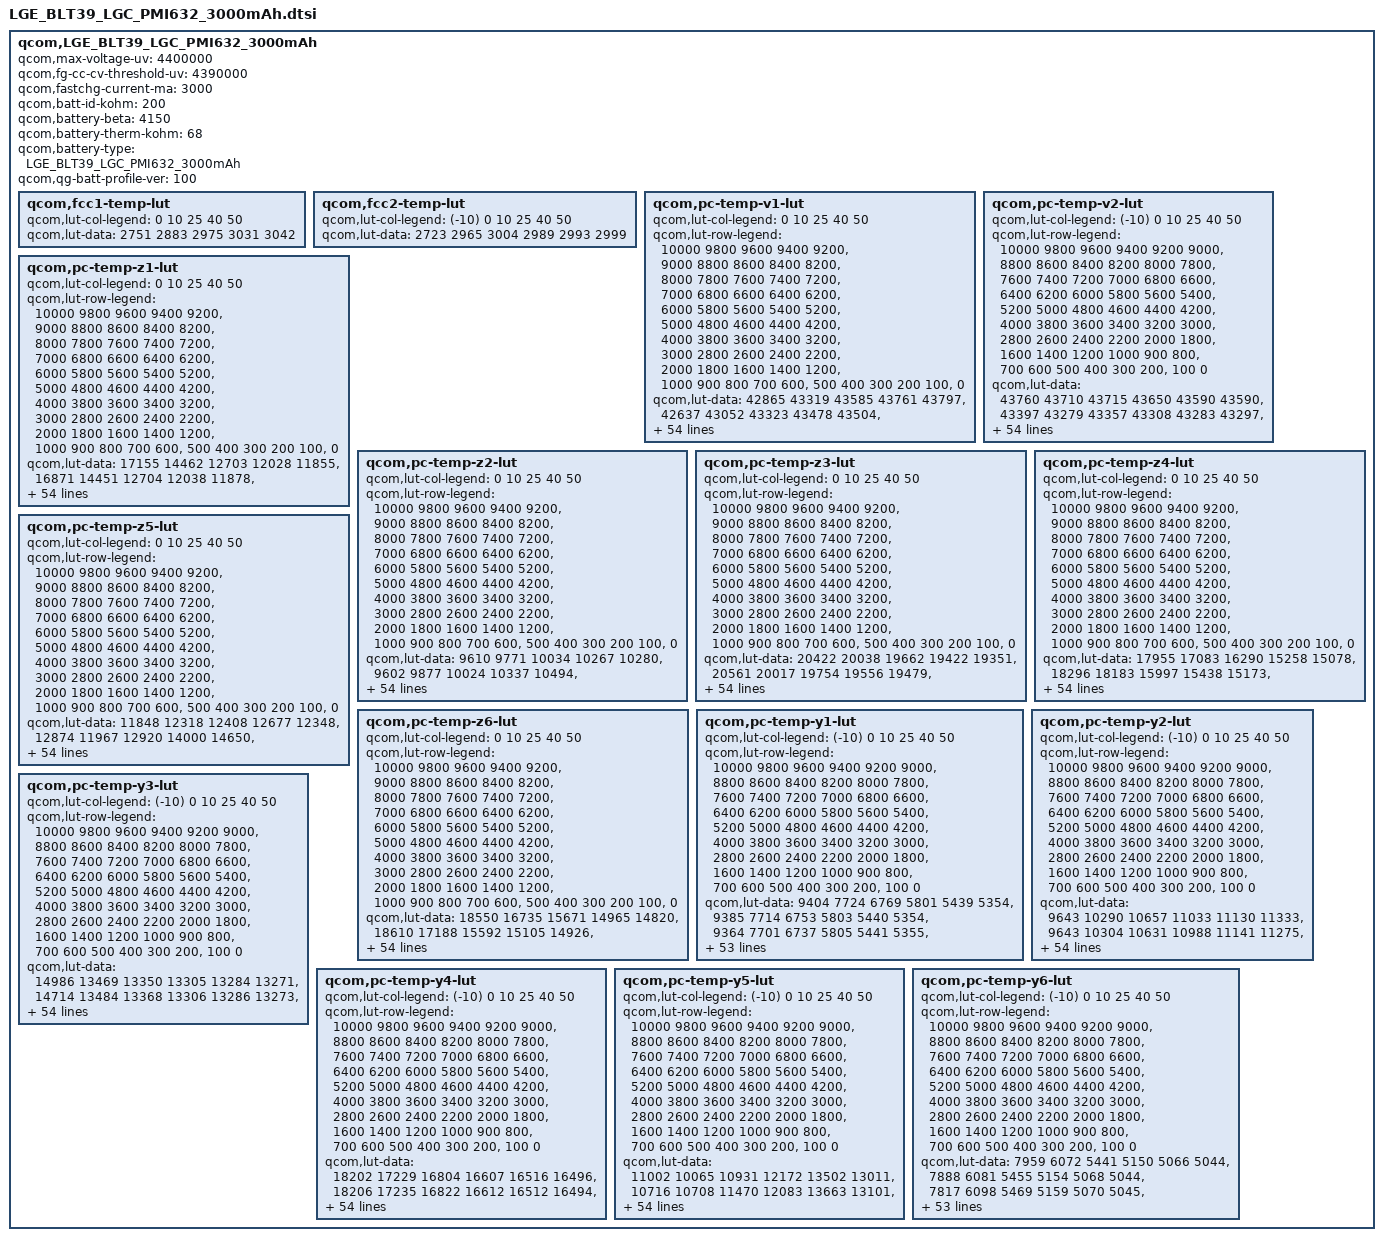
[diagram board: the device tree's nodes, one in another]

qcom,LGE_BLT39_LGC_PMI632_3000mAh {
    /* 3869837_LGE_BLT39lgc_3000mAh_averaged_MasterSlave_Feb22nd2019 */
    qcom,max-voltage-uv = <4400000>;
    qcom,fg-cc-cv-threshold-uv = <4390000>;
    qcom,fastchg-current-ma = <3000>;
    qcom,batt-id-kohm = <200>;
    qcom,battery-beta = <4150>;
    qcom,battery-therm-kohm = <68>;
    qcom,battery-type = "LGE_BLT39_LGC_PMI632_3000mAh";
    qcom,qg-batt-profile-ver = <100>;

	qcom,fcc1-temp-lut {
		qcom,lut-col-legend = <0 10 25 40 50>;
		qcom,lut-data = <2751 2883 2975 3031 3042>;
	};

	qcom,fcc2-temp-lut {
		qcom,lut-col-legend = <(-10) 0 10 25 40 50>;
		qcom,lut-data = <2723 2965 3004 2989 2993 2999>;
	};

	qcom,pc-temp-v1-lut {
		qcom,lut-col-legend = <0 10 25 40 50>;
		qcom,lut-row-legend = <10000 9800 9600 9400 9200>,
			<9000 8800 8600 8400 8200>,
			<8000 7800 7600 7400 7200>,
			<7000 6800 6600 6400 6200>,
			<6000 5800 5600 5400 5200>,
			<5000 4800 4600 4400 4200>,
			<4000 3800 3600 3400 3200>,
			<3000 2800 2600 2400 2200>,
			<2000 1800 1600 1400 1200>,
			<1000 900 800 700 600>,
			<500 400 300 200 100>,
			<0>;
		qcom,lut-data = <42865 43319 43585 43761 43797>,
			<42637 43052 43323 43478 43504>,
			<42409 42795 43070 43224 43248>,
			<42184 42546 42827 42980 43007>,
			<41964 42299 42591 42741 42770>,
			<41745 42058 42358 42508 42540>,
			<41533 41829 42128 42276 42310>,
			<41338 41609 41903 42045 42080>,
			<41159 41401 41681 41819 41853>,
			<40968 41215 41464 41595 41629>,
			<40730 41054 41261 41374 41408>,
			<40460 40877 41081 41160 41192>,
			<40206 40649 40895 40950 40978>,
			<39959 40399 40665 40746 40771>,
			<39736 40188 40408 40540 40571>,
			<39584 40002 40200 40340 40378>,
			<39483 39843 40043 40158 40192>,
			<39391 39722 39902 39990 40015>,
			<39274 39622 39755 39828 39845>,
			<39141 39514 39610 39673 39686>,
			<39011 39390 39464 39519 39530>,
			<38891 39264 39318 39362 39367>,
			<38775 39146 39172 39205 39198>,
			<38669 39034 39022 39027 39021>,
			<38570 38925 38870 38792 38814>,
			<38481 38815 38716 38580 38621>,
			<38406 38708 38545 38473 38504>,
			<38341 38610 38394 38402 38423>,
			<38285 38519 38299 38335 38344>,
			<38236 38438 38230 38266 38257>,
			<38193 38374 38180 38201 38176>,
			<38151 38318 38147 38139 38106>,
			<38109 38268 38119 38081 38045>,
			<38068 38223 38091 38029 37989>,
			<38033 38180 38066 37986 37941>,
			<38001 38139 38035 37944 37893>,
			<37975 38099 37998 37898 37833>,
			<37960 38053 37952 37851 37765>,
			<37952 37993 37885 37787 37690>,
			<37940 37920 37783 37696 37611>,
			<37888 37826 37673 37590 37521>,
			<37789 37696 37565 37475 37411>,
			<37674 37555 37443 37345 37281>,
			<37531 37405 37284 37185 37121>,
			<37372 37279 37151 37049 36985>,
			<37265 37186 37073 36975 36911>,
			<37225 37151 37048 36955 36893>,
			<37187 37123 37035 36945 36881>,
			<37144 37092 37012 36924 36861>,
			<37061 37030 36954 36861 36798>,
			<36839 36808 36695 36591 36524>,
			<36407 36358 36265 36157 36093>,
			<35831 35788 35696 35582 35527>,
			<35061 35014 34918 34798 34755>,
			<33812 33791 33706 33579 33568>,
			<30000 30000 30000 30000 30000>;
	};

	qcom,pc-temp-v2-lut {
		qcom,lut-col-legend = <(-10) 0 10 25 40 50>;
		qcom,lut-row-legend = <10000 9800 9600 9400 9200 9000>,
			<8800 8600 8400 8200 8000 7800>,
			<7600 7400 7200 7000 6800 6600>,
			<6400 6200 6000 5800 5600 5400>,
			<5200 5000 4800 4600 4400 4200>,
			<4000 3800 3600 3400 3200 3000>,
			<2800 2600 2400 2200 2000 1800>,
			<1600 1400 1200 1000 900 800>,
			<700 600 500 400 300 200>,
			<100 0>;
		qcom,lut-data = <43760 43710 43715 43650 43590 43590>,
			<43397 43279 43357 43308 43283 43297>,
			<43057 42900 43035 43000 43000 43025>,
			<42741 42583 42755 42732 42743 42772>,
			<42439 42318 42511 42498 42511 42541>,
			<42165 42072 42279 42274 42287 42315>,
			<41941 41827 42048 42046 42059 42087>,
			<41757 41593 41825 41823 41835 41863>,
			<41579 41370 41604 41603 41614 41641>,
			<41369 41155 41384 41385 41395 41423>,
			<41139 40954 41179 41175 41180 41209>,
			<40930 40788 41007 40984 40972 40998>,
			<40775 40634 40839 40797 40768 40791>,
			<40632 40405 40614 40583 40566 40591>,
			<40428 39998 40313 40328 40362 40394>,
			<40035 39638 40033 40101 40169 40206>,
			<39612 39482 39811 39943 39997 40028>,
			<39370 39378 39616 39807 39833 39857>,
			<39224 39252 39441 39649 39672 39692>,
			<39093 39086 39287 39467 39519 39537>,
			<38936 38916 39135 39278 39352 39370>,
			<38770 38761 38977 39079 39141 39165>,
			<38613 38614 38822 38880 38917 38949>,
			<38465 38469 38679 38717 38741 38773>,
			<38327 38319 38545 38580 38599 38623>,
			<38215 38182 38423 38461 38477 38494>,
			<38125 38074 38312 38356 38372 38386>,
			<38050 37981 38209 38263 38278 38291>,
			<37988 37912 38114 38176 38192 38202>,
			<37938 37864 38024 38095 38114 38121>,
			<37893 37824 37943 38021 38041 38047>,
			<37848 37786 37867 37954 37973 37979>,
			<37804 37751 37800 37892 37909 37915>,
			<37759 37714 37751 37828 37843 37850>,
			<37713 37674 37716 37762 37779 37786>,
			<37665 37630 37678 37698 37709 37711>,
			<37613 37583 37634 37640 37622 37606>,
			<37557 37530 37585 37586 37526 37486>,
			<37495 37473 37528 37522 37441 37392>,
			<37429 37412 37464 37451 37370 37318>,
			<37358 37345 37388 37369 37293 37239>,
			<37277 37271 37285 37262 37188 37135>,
			<37185 37188 37174 37136 37065 37014>,
			<37081 37099 37074 36992 36911 36854>,
			<36955 37000 36987 36901 36831 36778>,
			<36800 36886 36905 36868 36806 36755>,
			<36703 36819 36875 36852 36793 36741>,
			<36584 36749 36839 36826 36770 36719>,
			<36431 36659 36779 36752 36711 36666>,
			<36216 36517 36631 36512 36494 36487>,
			<35919 36246 36265 36088 36097 36104>,
			<35520 35813 35767 35542 35570 35603>,
			<34899 35178 35116 34840 34940 35001>,
			<33975 34261 34265 34070 34217 34311>,
			<32665 33075 33135 33055 33051 33209>,
			<28045 27812 27718 27711 27670 29741>;
	};

	qcom,pc-temp-z1-lut {
		qcom,lut-col-legend = <0 10 25 40 50>;
		qcom,lut-row-legend = <10000 9800 9600 9400 9200>,
			<9000 8800 8600 8400 8200>,
			<8000 7800 7600 7400 7200>,
			<7000 6800 6600 6400 6200>,
			<6000 5800 5600 5400 5200>,
			<5000 4800 4600 4400 4200>,
			<4000 3800 3600 3400 3200>,
			<3000 2800 2600 2400 2200>,
			<2000 1800 1600 1400 1200>,
			<1000 900 800 700 600>,
			<500 400 300 200 100>,
			<0>;
		qcom,lut-data = <17155 14462 12703 12028 11855>,
			<16871 14451 12704 12038 11878>,
			<16754 14448 12702 12041 11885>,
			<16665 14443 12698 12042 11890>,
			<16593 14433 12695 12043 11896>,
			<16520 14414 12692 12044 11901>,
			<16455 14392 12689 12045 11904>,
			<16411 14363 12688 12047 11905>,
			<16373 14335 12690 12048 11906>,
			<16324 14317 12696 12049 11907>,
			<16217 14304 12704 12050 11908>,
			<16056 14294 12717 12052 11909>,
			<15943 14274 12727 12057 11911>,
			<15886 14248 12715 12060 11913>,
			<15840 14237 12684 12058 11914>,
			<15784 14227 12673 12054 11916>,
			<15706 14221 12681 12055 11917>,
			<15632 14232 12693 12060 11919>,
			<15579 14261 12706 12064 11920>,
			<15534 14295 12721 12066 11923>,
			<15507 14347 12730 12067 11925>,
			<15506 14397 12734 12069 11926>,
			<15517 14414 12738 12072 11927>,
			<15521 14424 12745 12075 11928>,
			<15499 14432 12757 12079 11930>,
			<15475 14450 12765 12083 11934>,
			<15479 14476 12769 12086 11937>,
			<15513 14493 12773 12089 11942>,
			<15541 14504 12779 12093 11946>,
			<15538 14515 12786 12099 11950>,
			<15524 14531 12793 12105 11954>,
			<15520 14551 12800 12110 11958>,
			<15542 14570 12807 12116 11962>,
			<15573 14592 12814 12120 11964>,
			<15590 14609 12820 12124 11965>,
			<15598 14611 12828 12127 11966>,
			<15609 14610 12839 12131 11968>,
			<15654 14609 12853 12135 11970>,
			<15784 14621 12866 12138 11972>,
			<15887 14641 12880 12140 11974>,
			<15918 14647 12892 12143 11976>,
			<15936 14629 12901 12147 11979>,
			<15955 14625 12907 12151 11982>,
			<15976 14646 12910 12154 11984>,
			<15961 14622 12917 12158 11987>,
			<16020 14631 12924 12163 11989>,
			<16030 14628 12930 12163 11990>,
			<15969 14630 12930 12165 11992>,
			<16001 14600 12937 12167 11993>,
			<16021 14604 12948 12170 11995>,
			<16021 14667 12958 12178 12000>,
			<16056 14653 12985 12190 12011>,
			<16043 14677 13007 12209 12026>,
			<16038 14711 13065 12239 12049>,
			<16038 14711 13065 12239 12049>,
			<16038 14711 13065 12239 12049>;
	};

	qcom,pc-temp-z2-lut {
		qcom,lut-col-legend = <0 10 25 40 50>;
		qcom,lut-row-legend = <10000 9800 9600 9400 9200>,
			<9000 8800 8600 8400 8200>,
			<8000 7800 7600 7400 7200>,
			<7000 6800 6600 6400 6200>,
			<6000 5800 5600 5400 5200>,
			<5000 4800 4600 4400 4200>,
			<4000 3800 3600 3400 3200>,
			<3000 2800 2600 2400 2200>,
			<2000 1800 1600 1400 1200>,
			<1000 900 800 700 600>,
			<500 400 300 200 100>,
			<0>;
		qcom,lut-data = <9610 9771 10034 10267 10280>,
			<9602 9877 10024 10337 10494>,
			<9618 9837 10022 10291 10453>,
			<9649 9800 10030 10242 10408>,
			<9669 9794 10054 10204 10393>,
			<9682 9792 10085 10172 10384>,
			<9692 9791 10139 10172 10383>,
			<9699 9789 10179 10201 10403>,
			<9705 9789 10161 10233 10427>,
			<9709 9787 10111 10259 10442>,
			<9704 9785 10066 10283 10455>,
			<9690 9785 10026 10303 10463>,
			<9684 9795 9997 10322 10448>,
			<9696 9813 9984 10332 10431>,
			<9712 9814 9976 10298 10409>,
			<9718 9788 9974 10256 10378>,
			<9720 9765 9980 10264 10382>,
			<9722 9767 9992 10291 10406>,
			<9726 9773 10018 10315 10422>,
			<9732 9778 10063 10329 10431>,
			<9738 9787 10081 10344 10447>,
			<9741 9799 10082 10391 10518>,
			<9744 9809 10082 10481 10735>,
			<9744 9821 10097 10515 10845>,
			<9741 9830 10139 10494 10711>,
			<9735 9839 10160 10456 10544>,
			<9729 9847 10151 10388 10531>,
			<9721 9849 10139 10274 10559>,
			<9712 9847 10147 10247 10588>,
			<9704 9844 10170 10492 10646>,
			<9695 9838 10184 10733 10699>,
			<9686 9827 10186 10670 10676>,
			<9677 9819 10186 10485 10596>,
			<9667 9814 10194 10424 10569>,
			<9655 9811 10213 10440 10641>,
			<9642 9811 10221 10467 10755>,
			<9622 9815 10213 10516 10898>,
			<9564 9822 10202 10594 11067>,
			<9416 9844 10205 10650 11115>,
			<9287 9877 10226 10695 11102>,
			<9233 9900 10242 10719 11084>,
			<9197 9914 10247 10705 11066>,
			<9171 9933 10253 10685 11046>,
			<9159 9967 10266 10724 11033>,
			<9169 9804 10331 10773 10955>,
			<9170 9735 10356 10746 10801>,
			<9171 9730 10356 10737 10786>,
			<9170 9715 10272 10601 10803>,
			<9159 9703 10318 10603 10842>,
			<9153 9705 10333 10672 11027>,
			<9169 9696 10449 10825 10842>,
			<9192 9631 10294 10752 10630>,
			<9182 9530 10248 10617 10523>,
			<9153 9433 10123 10440 10370>,
			<9153 9433 10123 10440 10370>,
			<9153 9433 10123 10440 10370>;
	};

	qcom,pc-temp-z3-lut {
		qcom,lut-col-legend = <0 10 25 40 50>;
		qcom,lut-row-legend = <10000 9800 9600 9400 9200>,
			<9000 8800 8600 8400 8200>,
			<8000 7800 7600 7400 7200>,
			<7000 6800 6600 6400 6200>,
			<6000 5800 5600 5400 5200>,
			<5000 4800 4600 4400 4200>,
			<4000 3800 3600 3400 3200>,
			<3000 2800 2600 2400 2200>,
			<2000 1800 1600 1400 1200>,
			<1000 900 800 700 600>,
			<500 400 300 200 100>,
			<0>;
		qcom,lut-data = <20422 20038 19662 19422 19351>,
			<20561 20017 19754 19556 19479>,
			<20605 19975 19810 19594 19515>,
			<20632 19944 19825 19609 19529>,
			<20637 19952 19834 19612 19528>,
			<20630 19977 19834 19614 19521>,
			<20617 19988 19817 19609 19512>,
			<20599 19984 19794 19582 19499>,
			<20568 19977 19774 19553 19484>,
			<20541 19966 19754 19533 19467>,
			<20531 19949 19735 19514 19448>,
			<20525 19931 19716 19498 19433>,
			<20516 19914 19697 19484 19417>,
			<20496 19899 19673 19469 19403>,
			<20466 19887 19647 19451 19383>,
			<20427 19879 19627 19434 19363>,
			<20363 19870 19612 19424 19355>,
			<20300 19849 19600 19415 19352>,
			<20261 19815 19585 19408 19350>,
			<20233 19786 19571 19401 19349>,
			<20210 19760 19567 19396 19348>,
			<20190 19742 19573 19403 19355>,
			<20173 19741 19583 19427 19385>,
			<20161 19752 19595 19445 19400>,
			<20153 19770 19615 19457 19394>,
			<20145 19829 19629 19465 19380>,
			<20135 19919 19639 19452 19361>,
			<20120 19966 19645 19413 19331>,
			<20104 19996 19643 19394 19321>,
			<20086 20012 19635 19392 19372>,
			<20066 20008 19625 19396 19428>,
			<20047 19992 19612 19418 19429>,
			<20028 19975 19598 19462 19416>,
			<20008 19957 19587 19475 19403>,
			<19985 19937 19578 19461 19388>,
			<19961 19913 19574 19446 19377>,
			<19928 19886 19578 19438 19381>,
			<19874 19858 19584 19432 19391>,
			<19780 19822 19584 19431 19394>,
			<19690 19787 19581 19431 19389>,
			<19620 19780 19577 19432 19382>,
			<19568 19787 19566 19425 19370>,
			<19563 19785 19552 19416 19359>,
			<19566 19731 19536 19418 19364>,
			<19558 19493 19505 19410 19360>,
			<19552 19412 19475 19388 19345>,
			<19538 19396 19467 19384 19345>,
			<19527 19374 19376 19352 19332>,
			<19516 19366 19354 19353 19327>,
			<19503 19364 19368 19346 19318>,
			<19526 19372 19386 19328 19327>,
			<19582 19402 19360 19329 19336>,
			<19600 19421 19354 19342 19340>,
			<19669 19428 19353 19349 19354>,
			<19669 19428 19353 19349 19354>,
			<19669 19428 19353 19349 19354>;
	};

	qcom,pc-temp-z4-lut {
		qcom,lut-col-legend = <0 10 25 40 50>;
		qcom,lut-row-legend = <10000 9800 9600 9400 9200>,
			<9000 8800 8600 8400 8200>,
			<8000 7800 7600 7400 7200>,
			<7000 6800 6600 6400 6200>,
			<6000 5800 5600 5400 5200>,
			<5000 4800 4600 4400 4200>,
			<4000 3800 3600 3400 3200>,
			<3000 2800 2600 2400 2200>,
			<2000 1800 1600 1400 1200>,
			<1000 900 800 700 600>,
			<500 400 300 200 100>,
			<0>;
		qcom,lut-data = <17955 17083 16290 15258 15078>,
			<18296 18183 15997 15438 15173>,
			<18021 17780 15759 15304 15108>,
			<17509 17277 15581 15165 15023>,
			<17158 16923 15436 15084 14962>,
			<16942 16604 15323 15021 14907>,
			<16766 16358 15229 14978 14881>,
			<16606 16179 15156 14946 14869>,
			<16456 16031 15102 14925 14861>,
			<16348 15888 15059 14912 14855>,
			<16293 15751 15029 14904 14849>,
			<16256 15648 15005 14897 14844>,
			<16209 15581 14991 14890 14836>,
			<16131 15531 14995 14883 14831>,
			<16039 15492 15005 14877 14832>,
			<15953 15461 15006 14872 14830>,
			<15857 15435 14965 14863 14822>,
			<15791 15406 14920 14844 14805>,
			<15785 15377 14911 14829 14787>,
			<15786 15368 14907 14818 14772>,
			<15788 15377 14901 14809 14760>,
			<15791 15387 14882 14800 14757>,
			<15799 15383 14865 14788 14756>,
			<15809 15357 14865 14788 14757>,
			<15831 15321 14868 14890 14849>,
			<15856 15246 14875 15002 14964>,
			<15868 15146 14938 15011 14979>,
			<15877 15092 15007 15010 14981>,
			<15882 15060 15014 15008 14979>,
			<15883 15039 15011 14985 14901>,
			<15882 15032 15005 14950 14806>,
			<15882 15028 14988 14899 14778>,
			<15881 15024 14961 14827 14764>,
			<15880 15017 14937 14797 14759>,
			<15878 15011 14913 14789 14757>,
			<15872 15005 14888 14785 14757>,
			<15866 15000 14855 14786 14765>,
			<15869 14995 14828 14790 14786>,
			<15877 14986 14829 14796 14798>,
			<15883 14975 14846 14814 14804>,
			<15877 14957 14855 14828 14807>,
			<15856 14920 14844 14824 14804>,
			<15788 14907 14834 14815 14799>,
			<15615 14913 14835 14809 14797>,
			<15312 15019 14805 14788 14784>,
			<15312 15069 14774 14755 14753>,
			<15318 15077 14764 14735 14728>,
			<15316 15084 14842 14732 14705>,
			<15311 15078 14847 14705 14681>,
			<15300 15065 14824 14721 14703>,
			<15270 15061 14854 14794 14735>,
			<15270 15095 14911 14797 14728>,
			<15344 15113 14928 14786 14723>,
			<15363 15148 14945 14781 14711>,
			<15363 15148 14945 14781 14711>,
			<15363 15148 14945 14781 14711>;
	};

	qcom,pc-temp-z5-lut {
		qcom,lut-col-legend = <0 10 25 40 50>;
		qcom,lut-row-legend = <10000 9800 9600 9400 9200>,
			<9000 8800 8600 8400 8200>,
			<8000 7800 7600 7400 7200>,
			<7000 6800 6600 6400 6200>,
			<6000 5800 5600 5400 5200>,
			<5000 4800 4600 4400 4200>,
			<4000 3800 3600 3400 3200>,
			<3000 2800 2600 2400 2200>,
			<2000 1800 1600 1400 1200>,
			<1000 900 800 700 600>,
			<500 400 300 200 100>,
			<0>;
		qcom,lut-data = <11848 12318 12408 12677 12348>,
			<12874 11967 12920 14000 14650>,
			<13759 12415 13342 14584 15471>,
			<14576 13065 13654 14976 15951>,
			<15369 13767 13914 15335 16423>,
			<16141 14611 14187 15595 16809>,
			<16888 15305 14497 15644 16885>,
			<17640 15835 14767 15640 16695>,
			<18427 16275 14965 15620 16410>,
			<19030 16647 15126 15439 16009>,
			<19329 16995 15204 15143 15516>,
			<19529 17156 15193 14964 15225>,
			<19823 16879 15103 14823 14977>,
			<20489 16321 14771 14660 14786>,
			<21286 15889 14195 14393 14329>,
			<21799 15545 14023 14173 13710>,
			<22199 15219 14507 14220 13633>,
			<22441 14901 15091 14455 13859>,
			<22434 14589 15316 14593 14163>,
			<22335 14260 15448 14725 14463>,
			<22209 13843 15691 14990 14915>,
			<22033 13487 16535 16068 16681>,
			<21770 13372 17923 18971 21708>,
			<21478 13392 20219 21754 24279>,
			<21136 13538 23981 24677 22925>,
			<20757 14694 27051 26770 20504>,
			<20378 16821 29578 24968 17907>,
			<19965 18686 31264 19327 14710>,
			<19545 20868 30863 16261 13502>,
			<19132 22307 28777 15182 15080>,
			<18708 22276 26616 14619 17302>,
			<18306 21996 24486 15869 18558>,
			<17958 21696 22536 19253 19505>,
			<17611 21238 21323 21182 20313>,
			<17185 20624 20381 21969 20928>,
			<16670 19932 20053 22535 21611>,
			<16023 19072 21072 23097 23119>,
			<15045 18375 22829 23591 25238>,
			<13529 17762 24425 23579 25643>,
			<12264 17189 26195 22268 22757>,
			<11570 17361 26963 20765 19532>,
			<11121 19465 24480 19834 17975>,
			<11022 20141 21623 19201 17032>,
			<11003 18176 20394 18977 16778>,
			<11596 13355 20310 19008 16682>,
			<11536 11950 18854 18622 16699>,
			<11418 11738 18237 18682 17571>,
			<11346 11503 13098 16016 17453>,
			<11269 11449 12551 17364 19213>,
			<11216 11461 13088 16280 16512>,
			<11437 11631 13640 13120 14102>,
			<11768 11794 12270 12794 14290>,
			<11517 11682 11982 12995 14363>,
			<11474 11502 11753 13092 15302>,
			<11474 11502 11753 13092 15302>,
			<11474 11502 11753 13092 15302>;
	};

	qcom,pc-temp-z6-lut {
		qcom,lut-col-legend = <0 10 25 40 50>;
		qcom,lut-row-legend = <10000 9800 9600 9400 9200>,
			<9000 8800 8600 8400 8200>,
			<8000 7800 7600 7400 7200>,
			<7000 6800 6600 6400 6200>,
			<6000 5800 5600 5400 5200>,
			<5000 4800 4600 4400 4200>,
			<4000 3800 3600 3400 3200>,
			<3000 2800 2600 2400 2200>,
			<2000 1800 1600 1400 1200>,
			<1000 900 800 700 600>,
			<500 400 300 200 100>,
			<0>;
		qcom,lut-data = <18550 16735 15671 14965 14820>,
			<18610 17188 15592 15105 14926>,
			<18471 16982 15519 15069 14915>,
			<18206 16735 15452 15029 14897>,
			<18008 16578 15390 15000 14875>,
			<17874 16445 15336 14973 14848>,
			<17756 16337 15285 14947 14830>,
			<17639 16252 15242 14920 14818>,
			<17525 16178 15209 14898 14807>,
			<17425 16103 15181 14882 14795>,
			<17344 16030 15160 14869 14784>,
			<17275 15968 15143 14857 14772>,
			<17201 15917 15129 14847 14762>,
			<17114 15875 15116 14836 14751>,
			<17025 15850 15104 14824 14741>,
			<16938 15836 15089 14813 14730>,
			<16844 15824 15065 14801 14720>,
			<16770 15805 15043 14789 14711>,
			<16736 15786 15033 14778 14703>,
			<16714 15778 15027 14769 14695>,
			<16698 15780 15023 14763 14689>,
			<16685 15783 15020 14763 14690>,
			<16675 15785 15018 14769 14701>,
			<16672 15787 15021 14781 14718>,
			<16688 15789 15033 14832 14756>,
			<16709 15796 15050 14882 14794>,
			<16717 15804 15084 14880 14795>,
			<16723 15811 15114 14863 14782>,
			<16726 15818 15116 14848 14771>,
			<16726 15822 15112 14838 14764>,
			<16725 15820 15106 14829 14757>,
			<16725 15816 15093 14821 14747>,
			<16726 15812 15076 14814 14735>,
			<16727 15806 15061 14806 14725>,
			<16727 15800 15047 14796 14715>,
			<16724 15792 15036 14787 14709>,
			<16718 15783 15026 14785 14715>,
			<16713 15772 15019 14783 14729>,
			<16707 15758 15020 14783 14733>,
			<16703 15742 15029 14791 14733>,
			<16718 15730 15033 14798 14732>,
			<16743 15722 15025 14793 14726>,
			<16742 15710 15015 14785 14718>,
			<16725 15685 15009 14784 14719>,
			<16593 15601 14982 14772 14713>,
			<16589 15582 14953 14747 14691>,
			<16583 15577 14945 14736 14680>,
			<16579 15569 14933 14718 14663>,
			<16572 15566 14925 14707 14650>,
			<16562 15566 14925 14710 14655>,
			<16568 15577 14952 14734 14676>,
			<16608 15621 14970 14740 14680>,
			<16656 15656 14984 14745 14684>,
			<16715 15704 15006 14754 14691>,
			<16715 15704 15006 14754 14691>,
			<16715 15704 15006 14754 14691>;
	};

	qcom,pc-temp-y1-lut {
		qcom,lut-col-legend = <(-10) 0 10 25 40 50>;
		qcom,lut-row-legend = <10000 9800 9600 9400 9200 9000>,
			<8800 8600 8400 8200 8000 7800>,
			<7600 7400 7200 7000 6800 6600>,
			<6400 6200 6000 5800 5600 5400>,
			<5200 5000 4800 4600 4400 4200>,
			<4000 3800 3600 3400 3200 3000>,
			<2800 2600 2400 2200 2000 1800>,
			<1600 1400 1200 1000 900 800>,
			<700 600 500 400 300 200>,
			<100 0>;
		qcom,lut-data = <9404 7724 6769 5801 5439 5354>,
			<9385 7714 6753 5803 5440 5354>,
			<9364 7701 6737 5805 5441 5355>,
			<9341 7690 6724 5806 5442 5357>,
			<9318 7681 6716 5808 5443 5357>,
			<9296 7678 6712 5808 5443 5358>,
			<9270 7679 6727 5808 5444 5358>,
			<9224 7682 6750 5807 5444 5359>,
			<9191 7686 6750 5806 5444 5359>,
			<9207 7700 6726 5804 5444 5360>,
			<9259 7714 6710 5803 5444 5361>,
			<9291 7723 6708 5802 5444 5361>,
			<9265 7733 6706 5803 5444 5361>,
			<9218 7739 6707 5804 5445 5361>,
			<9198 7739 6713 5808 5446 5362>,
			<9197 7736 6720 5813 5447 5363>,
			<9197 7729 6731 5816 5447 5364>,
			<9194 7716 6745 5820 5448 5366>,
			<9172 7713 6749 5820 5449 5367>,
			<9151 7732 6749 5821 5450 5367>,
			<9150 7750 6748 5821 5451 5366>,
			<9162 7745 6743 5823 5452 5367>,
			<9171 7726 6737 5826 5453 5367>,
			<9166 7720 6739 5828 5453 5368>,
			<9155 7725 6750 5831 5454 5368>,
			<9141 7733 6758 5834 5455 5369>,
			<9118 7743 6761 5837 5456 5371>,
			<9095 7756 6764 5839 5458 5372>,
			<9096 7761 6769 5843 5461 5374>,
			<9140 7743 6777 5850 5463 5375>,
			<9181 7723 6782 5855 5466 5376>,
			<9173 7726 6782 5857 5468 5378>,
			<9135 7743 6781 5858 5469 5380>,
			<9106 7751 6778 5860 5471 5382>,
			<9093 7741 6772 5865 5474 5383>,
			<9083 7730 6770 5870 5477 5384>,
			<9077 7736 6789 5873 5479 5386>,
			<9091 7756 6818 5876 5481 5387>,
			<9106 7769 6830 5878 5482 5388>,
			<9105 7768 6842 5883 5483 5389>,
			<9113 7763 6848 5887 5484 5391>,
			<9130 7758 6820 5891 5487 5393>,
			<9130 7744 6798 5895 5491 5395>,
			<9103 7745 6817 5907 5494 5397>,
			<9084 7756 6818 5916 5497 5400>,
			<9113 7767 6855 5913 5498 5401>,
			<9147 7821 6848 5920 5501 5401>,
			<9176 7812 6836 5927 5501 5403>,
			<9189 7794 6845 5930 5504 5403>,
			<9184 7924 6885 5939 5507 5405>,
			<9176 7872 6907 5953 5516 5410>,
			<9180 7917 6919 5984 5528 5420>,
			<9250 7916 6949 6019 5546 5434>,
			<9449 7968 6956 6062 5571 5452>,
			<9449 7968 6956 6062 5571 5452>,
			<9449 7968 6956 6062 5571 5452>;
	};

	qcom,pc-temp-y2-lut {
		qcom,lut-col-legend = <(-10) 0 10 25 40 50>;
		qcom,lut-row-legend = <10000 9800 9600 9400 9200 9000>,
			<8800 8600 8400 8200 8000 7800>,
			<7600 7400 7200 7000 6800 6600>,
			<6400 6200 6000 5800 5600 5400>,
			<5200 5000 4800 4600 4400 4200>,
			<4000 3800 3600 3400 3200 3000>,
			<2800 2600 2400 2200 2000 1800>,
			<1600 1400 1200 1000 900 800>,
			<700 600 500 400 300 200>,
			<100 0>;
		qcom,lut-data = <9643 10290 10657 11033 11130 11333>,
			<9643 10304 10631 10988 11141 11275>,
			<9643 10311 10605 10933 11141 11219>,
			<9683 10311 10582 10878 11131 11167>,
			<9751 10307 10561 10832 11115 11118>,
			<9821 10299 10543 10803 11095 11075>,
			<9896 10263 10529 10789 11062 11031>,
			<9989 10211 10517 10779 11025 10995>,
			<10050 10209 10508 10770 11014 11007>,
			<9986 10294 10503 10758 11019 11105>,
			<9791 10377 10496 10748 11024 11174>,
			<9675 10410 10481 10738 11020 11178>,
			<9828 10433 10466 10729 11015 11178>,
			<10099 10441 10477 10732 11021 11170>,
			<10188 10442 10545 10762 11047 11128>,
			<9976 10445 10598 10794 11074 11105>,
			<9718 10460 10612 10815 11105 11160>,
			<9666 10491 10622 10832 11148 11260>,
			<9665 10514 10636 10838 11194 11338>,
			<9665 10527 10653 10838 11252 11417>,
			<9664 10538 10670 10840 11284 11470>,
			<9663 10551 10685 10859 11279 11493>,
			<9663 10563 10698 10896 11269 11509>,
			<9662 10566 10710 10931 11259 11490>,
			<9660 10549 10721 10968 11231 11380>,
			<9659 10527 10732 10995 11212 11309>,
			<9658 10517 10742 11007 11239 11339>,
			<9658 10510 10750 11014 11299 11409>,
			<9657 10501 10751 11015 11353 11509>,
			<9657 10486 10750 11005 11412 11681>,
			<9656 10461 10750 10997 11451 11812>,
			<9656 10319 10750 10996 11464 11871>,
			<9655 9939 10751 10994 11472 11909>,
			<9655 9730 10744 10989 11471 11916>,
			<9655 9698 10708 10969 11449 11917>,
			<9654 9680 10671 10946 11415 11917>,
			<9654 9670 10645 10933 11349 11782>,
			<9654 9664 10620 10921 11261 11555>,
			<9653 9659 10587 10906 11222 11454>,
			<9653 9657 10548 10886 11203 11398>,
			<9653 9655 10504 10870 11193 11375>,
			<9653 9653 10457 10864 11190 11387>,
			<9653 9653 10403 10858 11189 11411>,
			<9653 9652 10335 10809 11149 11472>,
			<9652 9652 10262 10746 11121 11411>,
			<9652 9651 10264 10728 11140 11253>,
			<9652 9652 10245 10711 11114 11271>,
			<9652 9651 10218 10703 11085 11218>,
			<9652 9651 10194 10683 11056 11221>,
			<9652 9651 10122 10647 11049 11117>,
			<9652 9651 9752 10588 10954 11074>,
			<9652 9651 9695 10511 10865 10934>,
			<9651 9651 9674 10443 10738 10818>,
			<9650 9650 9663 10445 10699 10736>,
			<9650 9650 9663 10445 10699 10736>,
			<9650 9650 9663 10445 10699 10736>;
	};

	qcom,pc-temp-y3-lut {
		qcom,lut-col-legend = <(-10) 0 10 25 40 50>;
		qcom,lut-row-legend = <10000 9800 9600 9400 9200 9000>,
			<8800 8600 8400 8200 8000 7800>,
			<7600 7400 7200 7000 6800 6600>,
			<6400 6200 6000 5800 5600 5400>,
			<5200 5000 4800 4600 4400 4200>,
			<4000 3800 3600 3400 3200 3000>,
			<2800 2600 2400 2200 2000 1800>,
			<1600 1400 1200 1000 900 800>,
			<700 600 500 400 300 200>,
			<100 0>;
		qcom,lut-data = <14986 13469 13350 13305 13284 13271>,
			<14714 13484 13368 13306 13286 13273>,
			<14468 13517 13386 13309 13290 13276>,
			<14262 13557 13403 13311 13293 13278>,
			<14111 13590 13417 13313 13296 13280>,
			<14028 13605 13428 13314 13298 13282>,
			<14033 13605 13436 13316 13299 13282>,
			<14125 13604 13441 13317 13299 13283>,
			<14205 13609 13445 13320 13299 13285>,
			<14125 13641 13447 13329 13299 13292>,
			<13879 13667 13450 13335 13299 13297>,
			<13732 13644 13463 13338 13303 13296>,
			<13755 13592 13479 13340 13309 13295>,
			<13798 13551 13478 13340 13309 13293>,
			<13811 13517 13462 13340 13306 13290>,
			<13772 13497 13446 13340 13304 13288>,
			<13723 13506 13434 13346 13305 13291>,
			<13714 13526 13424 13354 13307 13296>,
			<13717 13532 13419 13356 13309 13298>,
			<13720 13524 13417 13353 13310 13299>,
			<13717 13512 13414 13349 13311 13299>,
			<13705 13501 13410 13342 13308 13296>,
			<13693 13489 13405 13334 13301 13290>,
			<13683 13476 13400 13326 13295 13286>,
			<13675 13465 13394 13319 13290 13282>,
			<13673 13452 13390 13315 13287 13280>,
			<13673 13428 13387 13317 13286 13279>,
			<13673 13394 13384 13320 13286 13278>,
			<13680 13381 13383 13321 13286 13279>,
			<13719 13387 13381 13322 13289 13281>,
			<13770 13397 13379 13323 13292 13282>,
			<13813 13409 13372 13325 13294 13283>,
			<13856 13429 13364 13328 13295 13284>,
			<13907 13453 13366 13328 13296 13285>,
			<13970 13481 13378 13328 13295 13285>,
			<14043 13517 13388 13327 13295 13285>,
			<14121 13560 13391 13327 13292 13283>,
			<14200 13613 13393 13327 13288 13279>,
			<14285 13685 13399 13328 13287 13279>,
			<14380 13801 13409 13329 13287 13279>,
			<14488 13956 13415 13331 13287 13279>,
			<14601 14135 13414 13329 13287 13279>,
			<14713 14352 13413 13325 13287 13279>,
			<14825 14562 13419 13323 13288 13277>,
			<14939 14746 13434 13324 13291 13280>,
			<15057 14845 13427 13331 13296 13286>,
			<15115 14551 13446 13338 13300 13286>,
			<15170 14692 13469 13348 13305 13287>,
			<15218 14839 13492 13352 13307 13290>,
			<15255 14985 13508 13353 13302 13296>,
			<15299 15103 13504 13364 13314 13298>,
			<15383 15247 13580 13383 13319 13301>,
			<15662 15390 13694 13400 13325 13305>,
			<16468 15667 13899 13429 13333 13309>,
			<16468 15667 13899 13429 13333 13309>,
			<16468 15667 13899 13429 13333 13309>;
	};

	qcom,pc-temp-y4-lut {
		qcom,lut-col-legend = <(-10) 0 10 25 40 50>;
		qcom,lut-row-legend = <10000 9800 9600 9400 9200 9000>,
			<8800 8600 8400 8200 8000 7800>,
			<7600 7400 7200 7000 6800 6600>,
			<6400 6200 6000 5800 5600 5400>,
			<5200 5000 4800 4600 4400 4200>,
			<4000 3800 3600 3400 3200 3000>,
			<2800 2600 2400 2200 2000 1800>,
			<1600 1400 1200 1000 900 800>,
			<700 600 500 400 300 200>,
			<100 0>;
		qcom,lut-data = <18202 17229 16804 16607 16516 16496>,
			<18206 17235 16822 16612 16512 16494>,
			<18209 17246 16840 16617 16511 16493>,
			<18209 17261 16856 16624 16510 16493>,
			<18208 17280 16872 16632 16512 16493>,
			<18205 17301 16886 16641 16514 16494>,
			<18157 17326 16898 16652 16519 16500>,
			<17909 17355 16909 16663 16528 16508>,
			<17695 17377 16923 16668 16539 16510>,
			<17902 17391 16941 16671 16552 16508>,
			<18543 17412 16962 16674 16563 16507>,
			<18926 17568 16996 16689 16568 16515>,
			<18810 17836 17029 16714 16572 16532>,
			<18551 17868 17034 16732 16582 16550>,
			<18300 17463 17025 16745 16604 16570>,
			<18009 17114 17010 16760 16628 16587>,
			<17768 17129 16948 16794 16649 16597>,
			<17722 17186 16868 16832 16669 16606>,
			<17720 17203 16851 16836 16694 16622>,
			<17718 17167 16849 16805 16727 16650>,
			<17690 17116 16845 16760 16745 16666>,
			<17610 17079 16825 16693 16688 16632>,
			<17534 17043 16794 16618 16588 16572>,
			<17478 16997 16774 16598 16549 16537>,
			<17430 16917 16759 16595 16533 16511>,
			<17416 16854 16748 16593 16527 16500>,
			<17425 16860 16742 16595 16533 16506>,
			<17441 16887 16737 16599 16546 16518>,
			<17453 16902 16727 16604 16559 16530>,
			<17463 16903 16713 16614 16572 16544>,
			<17474 16903 16704 16626 16586 16559>,
			<17489 16921 16700 16637 16604 16580>,
			<17510 16971 16696 16648 16620 16599>,
			<17532 17018 16696 16649 16623 16607>,
			<17554 17051 16696 16633 16621 16610>,
			<17578 17081 16698 16617 16618 16612>,
			<17605 17114 16713 16609 16589 16577>,
			<17635 17147 16735 16604 16542 16522>,
			<17668 17180 16751 16602 16532 16512>,
			<17701 17209 16766 16602 16541 16515>,
			<17732 17239 16778 16602 16547 16516>,
			<17769 17274 16787 16605 16547 16515>,
			<17822 17315 16801 16609 16546 16513>,
			<17893 17356 16843 16589 16520 16500>,
			<17977 17393 16895 16588 16513 16497>,
			<18081 17407 16887 16628 16539 16511>,
			<18139 17286 16925 16648 16558 16530>,
			<18193 17319 16979 16685 16576 16546>,
			<18232 17358 17043 16716 16580 16544>,
			<18257 17380 17091 16677 16545 16505>,
			<18285 17360 17120 16673 16542 16512>,
			<18334 17332 17132 16730 16584 16557>,
			<18629 17321 17222 16902 16766 16707>,
			<19821 17464 17436 17504 17244 17111>,
			<19821 17464 17436 17504 17244 17111>,
			<19821 17464 17436 17504 17244 17111>;
	};

	qcom,pc-temp-y5-lut {
		qcom,lut-col-legend = <(-10) 0 10 25 40 50>;
		qcom,lut-row-legend = <10000 9800 9600 9400 9200 9000>,
			<8800 8600 8400 8200 8000 7800>,
			<7600 7400 7200 7000 6800 6600>,
			<6400 6200 6000 5800 5600 5400>,
			<5200 5000 4800 4600 4400 4200>,
			<4000 3800 3600 3400 3200 3000>,
			<2800 2600 2400 2200 2000 1800>,
			<1600 1400 1200 1000 900 800>,
			<700 600 500 400 300 200>,
			<100 0>;
		qcom,lut-data = <11002 10065 10931 12172 13502 13011>,
			<10716 10708 11470 12083 13663 13101>,
			<10566 11468 12035 11985 13735 13151>,
			<10537 12226 12573 11883 13736 13169>,
			<10614 12865 13030 11780 13686 13163>,
			<10782 13266 13353 11680 13603 13141>,
			<11388 13472 13562 11558 13400 12912>,
			<13701 13608 13719 11447 13075 12577>,
			<15630 13548 13849 11471 12751 12653>,
			<14814 12931 13976 11737 12365 13406>,
			<12099 12445 14034 11935 12162 13898>,
			<10482 13443 13886 11877 12350 13578>,
			<12298 15429 13662 11760 12657 12956>,
			<15521 15806 13857 11769 12637 12458>,
			<16588 13965 15019 11911 12159 11974>,
			<14213 12377 15737 12147 11833 11741>,
			<11339 12858 15243 12782 11878 11887>,
			<10813 14112 14515 13816 11993 12168>,
			<11052 14756 14458 14740 12186 12370>,
			<11259 14993 14799 15745 12685 12528>,
			<11267 15132 15068 16292 13356 12768>,
			<11235 15198 15168 16081 14459 13842>,
			<11187 15243 15230 15574 15653 15237>,
			<11052 15240 15193 14990 15718 15430>,
			<10837 14925 14973 14059 14615 15009>,
			<10662 14356 14789 13474 13674 14519>,
			<10504 13362 14744 13705 13388 13990>,
			<10385 11799 14748 14186 13201 13505>,
			<10368 11156 14795 14442 13244 13460>,
			<10403 11205 14969 14651 13766 13689>,
			<10442 11268 14995 14913 14364 13953>,
			<10463 11226 14301 15524 14797 14153>,
			<10477 11121 13423 16349 15201 14370>,
			<10491 11048 13487 16570 15580 14726>,
			<10512 11018 14351 16582 15997 15352>,
			<10545 10996 14845 16587 16219 15703>,
			<10576 10970 14612 16442 15906 15649>,
			<10605 10941 14295 16131 15206 15513>,
			<10641 10929 14309 15975 14600 15275>,
			<10698 10976 14571 15765 13995 14743>,
			<10802 11046 14712 15458 13538 14241>,
			<10916 11071 13832 14730 13269 13859>,
			<11000 11080 12887 13824 13125 13652>,
			<11073 11127 12418 13469 14162 13796>,
			<11156 11241 12276 12938 14440 14355>,
			<11285 11339 12139 12641 13389 14009>,
			<11351 11382 12437 12814 13141 13074>,
			<11391 11504 12756 12972 13025 12568>,
			<11393 11618 13121 12907 12985 12668>,
			<11358 11777 13255 13468 13378 15248>,
			<11291 11574 11709 14578 16956 17145>,
			<11173 11408 11668 16203 17234 17663>,
			<10826 11343 12050 16745 17781 17970>,
			<10243 11412 12963 16619 17201 17327>,
			<10243 11412 12963 16619 17201 17327>,
			<10243 11412 12963 16619 17201 17327>;
	};

	qcom,pc-temp-y6-lut {
		qcom,lut-col-legend = <(-10) 0 10 25 40 50>;
		qcom,lut-row-legend = <10000 9800 9600 9400 9200 9000>,
			<8800 8600 8400 8200 8000 7800>,
			<7600 7400 7200 7000 6800 6600>,
			<6400 6200 6000 5800 5600 5400>,
			<5200 5000 4800 4600 4400 4200>,
			<4000 3800 3600 3400 3200 3000>,
			<2800 2600 2400 2200 2000 1800>,
			<1600 1400 1200 1000 900 800>,
			<700 600 500 400 300 200>,
			<100 0>;
		qcom,lut-data = <7959 6072 5441 5150 5066 5044>,
			<7888 6081 5455 5154 5068 5044>,
			<7817 6098 5469 5159 5070 5045>,
			<7750 6118 5482 5163 5072 5047>,
			<7689 6135 5493 5167 5074 5048>,
			<7640 6143 5501 5171 5077 5050>,
			<7605 6144 5507 5174 5080 5053>,
			<7581 6144 5512 5178 5083 5055>,
			<7557 6146 5517 5182 5086 5058>,
			<7519 6157 5521 5188 5089 5062>,
			<7471 6173 5526 5194 5093 5065>,
			<7443 6203 5542 5201 5097 5069>,
			<7440 6242 5559 5208 5101 5072>,
			<7438 6238 5560 5213 5106 5075>,
			<7427 6108 5546 5217 5110 5078>,
			<7293 5996 5528 5221 5115 5082>,
			<7134 6006 5503 5235 5121 5087>,
			<7103 6036 5477 5251 5129 5093>,
			<7104 6045 5468 5254 5137 5100>,
			<7105 6032 5465 5242 5147 5108>,
			<7099 6014 5462 5226 5152 5113>,
			<7077 6001 5453 5202 5134 5101>,
			<7057 5990 5441 5175 5100 5079>,
			<7045 5976 5433 5164 5084 5065>,
			<7036 5953 5426 5159 5075 5054>,
			<7033 5935 5422 5156 5072 5050>,
			<7045 5934 5419 5158 5073 5051>,
			<7066 5936 5418 5161 5077 5054>,
			<7093 5940 5416 5165 5081 5058>,
			<7131 5961 5414 5169 5087 5063>,
			<7175 5995 5411 5173 5094 5069>,
			<7219 6032 5408 5179 5100 5076>,
			<7267 6078 5406 5184 5106 5082>,
			<7319 6131 5408 5185 5107 5085>,
			<7377 6191 5420 5180 5106 5086>,
			<7441 6262 5434 5176 5105 5087>,
			<7509 6344 5446 5176 5095 5075>,
			<7582 6440 5459 5175 5080 5057>,
			<7659 6553 5476 5175 5076 5054>,
			<7742 6693 5498 5178 5079 5055>,
			<7832 6854 5520 5180 5081 5056>,
			<7927 7031 5542 5181 5081 5056>,
			<8028 7226 5570 5181 5081 5055>,
			<8137 7410 5620 5176 5076 5050>,
			<8252 7567 5697 5177 5075 5051>,
			<8377 7649 5680 5196 5087 5061>,
			<8442 7408 5733 5208 5095 5066>,
			<8507 7522 5800 5228 5104 5072>,
			<8569 7650 5874 5242 5107 5074>,
			<8618 7774 5943 5235 5094 5066>,
			<8679 7865 5981 5244 5102 5070>,
			<8794 7971 6098 5282 5120 5087>,
			<9198 8092 6285 5352 5179 5134>,
			<10422 8387 6568 5555 5323 5255>,
			<10422 8387 6568 5555 5323 5255>,
			<10422 8387 6568 5555 5323 5255>;
	};

};
